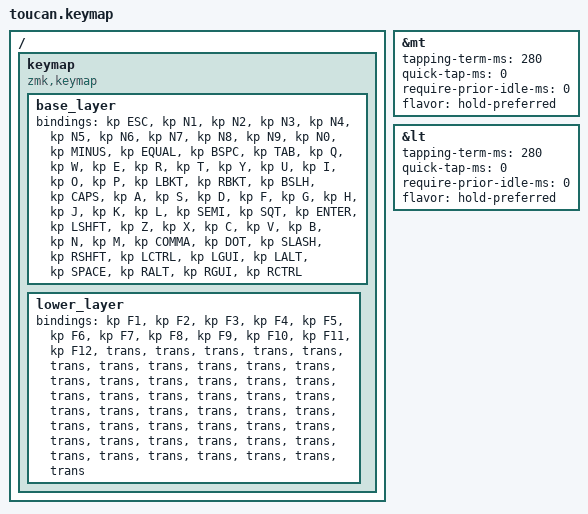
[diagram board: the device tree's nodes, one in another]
#include <behaviors.dtsi>
#include <dt-bindings/zmk/keys.h>
#include <dt-bindings/zmk/bt.h>
#include <dt-bindings/zmk/outputs.h>
#include <dt-bindings/zmk/ext_power.h>
#include <dt-bindings/zmk/rgb.h>
#include <dt-bindings/zmk/backlight.h>
#include <dt-bindings/zmk/mouse.h>
#include <dt-bindings/zmk/pointing.h>

&mt {
    tapping-term-ms = <280>;
    quick-tap-ms = <0>;
    require-prior-idle-ms = <0>;
    flavor = "hold-preferred";
};
&lt {
    tapping-term-ms = <280>;
    quick-tap-ms = <0>;
    require-prior-idle-ms = <0>;
    flavor = "hold-preferred";
};

/ {
  keymap {
    compatible = "zmk,keymap";

    base_layer {
      bindings = <
        &kp ESC
        &kp N1
        &kp N2
        &kp N3
        &kp N4
        &kp N5
        &kp N6
        &kp N7
        &kp N8
        &kp N9
        &kp N0
        &kp MINUS
        &kp EQUAL
        &kp BSPC
        &kp TAB
        &kp Q
        &kp W
        &kp E
        &kp R
        &kp T
        &kp Y
        &kp U
        &kp I
        &kp O
        &kp P
        &kp LBKT
        &kp RBKT
        &kp BSLH
        &kp CAPS
        &kp A
        &kp S
        &kp D
        &kp F
        &kp G
        &kp H
        &kp J
        &kp K
        &kp L
        &kp SEMI
        &kp SQT
        &kp ENTER
        &kp LSHFT
        &kp Z
        &kp X
        &kp C
        &kp V
        &kp B
        &kp N
        &kp M
        &kp COMMA
        &kp DOT
        &kp SLASH
        &kp RSHFT
        &kp LCTRL
        &kp LGUI
        &kp LALT
        &kp SPACE
        &kp RALT
        &kp RGUI
        &kp RCTRL
      >;
    };

    lower_layer {
      bindings = <
        &kp F1
        &kp F2
        &kp F3
        &kp F4
        &kp F5
        &kp F6
        &kp F7
        &kp F8
        &kp F9
        &kp F10
        &kp F11
        &kp F12
        &trans
        &trans
        &trans
        &trans
        &trans
        &trans
        &trans
        &trans
        &trans
        &trans
        &trans
        &trans
        &trans
        &trans
        &trans
        &trans
        &trans
        &trans
        &trans
        &trans
        &trans
        &trans
        &trans
        &trans
        &trans
        &trans
        &trans
        &trans
        &trans
        &trans
        &trans
        &trans
        &trans
        &trans
        &trans
        &trans
        &trans
        &trans
        &trans
        &trans
        &trans
        &trans
        &trans
        &trans
        &trans
        &trans
        &trans
        &trans
      >;
    };
  };
};
